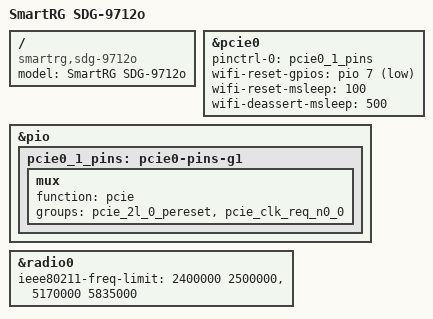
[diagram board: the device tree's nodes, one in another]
// SPDX-License-Identifier: (GPL-2.0 OR MIT)
/*
 * Copyright (C) 2024 SmartRG Inc.
 * Author: Chad Monroe <chad.monroe@smartrg.com>
 */

#include "mt7988d-smartrg-mt-stuart-phase2.dtsi"
#include "mt7988d-smartrg-SDG-9712o-power-limits-r1-RCM-AU-NZ.dtsi"
#include "mt7988d-smartrg-SDG-9712o-power-limits-r2-IC-CA.dtsi"
#include "mt7988d-smartrg-SDG-9712o-power-limits-r3-ETSI-GB.dtsi"
#include "mt7988d-smartrg-SDG-9712o-power-limits-r4-ETSI.dtsi"
#include "mt7988d-smartrg-SDG-9712o-power-limits-r5-FCC-US.dtsi"

/ {
	model = "SmartRG SDG-9712o";
	compatible = "smartrg,sdg-9712o", "mediatek,mt7988a";
};

&pcie0 {
	pinctrl-0 = <&pcie0_1_pins>;
	wifi-reset-gpios = <&pio 7 GPIO_ACTIVE_LOW>;
	wifi-reset-msleep = <100>;
	wifi-deassert-msleep = <500>;
};

&pio {
	pcie0_1_pins: pcie0-pins-g1 {
		mux {
			function = "pcie";
			groups = "pcie_2l_0_pereset", "pcie_clk_req_n0_0";
		};
	};
};

&radio0 {
	ieee80211-freq-limit = <2400000 2500000>, <5170000 5835000>;
};
